LIN_description_file;
LIN_protocol_version = "2.1";
LIN_language_version = "2.1";
LIN_speed = 19.2 kbps;

Nodes {
  Master: BCM_IntLightCmd, 1 ms, 0 ms ;
  Slaves: Headliner_Lamp, Cargo_Lamp_1, Cargo_Lamp_2, Cargo_Lamp_3, Cargo_Lamp_4, IP_Light, Footwell_Left, Footwell_Right, Base_Cargo_Lamp ;
}

Signals {
  LocationId_LampLIN_HL: 8, 0, BCM_IntLightCmd, Headliner_Lamp ;
  Intensity_LampLIN_TaskLH_HL: 7, 0, BCM_IntLightCmd, Headliner_Lamp ;
  UpdateIntensity_LampLIN_HL: 1, 0, BCM_IntLightCmd, Headliner_Lamp ;
  RampDuration_LampLIN_HL: 4, 0, BCM_IntLightCmd, Headliner_Lamp ;
  Headliner_Status: 1, 0, Headliner_Lamp, BCM_IntLightCmd ;
  Headliner_Status_OverVolt: 1, 0, Headliner_Lamp, BCM_IntLightCmd ;
  Headliner_Status_OverTemp: 1, 0, Headliner_Lamp, BCM_IntLightCmd ;
  Headliner_Status_ResponseError: 1, 0, Headliner_Lamp, BCM_IntLightCmd ;
  Headliner_Intensity_TaskLH: 7, 0, Headliner_Lamp, BCM_IntLightCmd ;
  CargoLamp_1_Status: 1, 0, Cargo_Lamp_1, BCM_IntLightCmd ;
  CargoLamp_1_Status_OverVolt: 1, 0, Cargo_Lamp_1, BCM_IntLightCmd ;
  CargoLamp_1_Status_ResponseError: 1, 0, Cargo_Lamp_1, BCM_IntLightCmd ;
  CargoLamp_1_Intensity: 7, 0, Cargo_Lamp_1, BCM_IntLightCmd ;
  CargoLamp_2_Status: 1, 0, Cargo_Lamp_2, BCM_IntLightCmd ;
  CargoLamp_2_Status_OverVolt: 1, 0, Cargo_Lamp_2, BCM_IntLightCmd ;
  CargoLamp_2_Status_ResponseError: 1, 0, Cargo_Lamp_2, BCM_IntLightCmd ;
  CargoLamp_2_Intensity: 7, 0, Cargo_Lamp_2, BCM_IntLightCmd ;
  CargoLamp_3_Status: 1, 0, Cargo_Lamp_3, BCM_IntLightCmd ;
  CargoLamp_3_Status_OverVolt: 1, 0, Cargo_Lamp_3, BCM_IntLightCmd ;
  CargoLamp_3_Status_ResponseError: 1, 0, Cargo_Lamp_3, BCM_IntLightCmd ;
  CargoLamp_3_Intensity: 7, 0, Cargo_Lamp_3, BCM_IntLightCmd ;
  CargoLamp_4_Status: 1, 0, Cargo_Lamp_4, BCM_IntLightCmd ;
  CargoLamp_4_Status_OverVolt: 1, 0, Cargo_Lamp_4, BCM_IntLightCmd ;
  CargoLamp_4_Status_ResponseError: 1, 0, Cargo_Lamp_4, BCM_IntLightCmd ;
  CargoLamp_4_Intensity: 7, 0, Cargo_Lamp_4, BCM_IntLightCmd ;
  IP_Light_Status: 1, 0, IP_Light, BCM_IntLightCmd ;
  IP_Light_Status_OverVolt: 1, 0, IP_Light, BCM_IntLightCmd ;
  IP_Light_Status_ResponseError: 1, 0, IP_Light, BCM_IntLightCmd ;
  IP_Light_Intensity: 7, 0, IP_Light, BCM_IntLightCmd ;
  FWLH_Status: 1, 0, Footwell_Left, BCM_IntLightCmd ;
  FWLH_Status_OverVolt: 1, 0, Footwell_Left, BCM_IntLightCmd ;
  FWLH_Status_OverTemp: 1, 0, Footwell_Left, BCM_IntLightCmd ;
  FWLH_Status_ResponseError: 1, 0, Footwell_Left, BCM_IntLightCmd ;
  FWLH_Intensity: 7, 0, Footwell_Left, BCM_IntLightCmd ;
  FWRH_Status: 1, 0, Footwell_Right, BCM_IntLightCmd ;
  FWRH_Status_OverVolt: 1, 0, Footwell_Right, BCM_IntLightCmd ;
  FWRH_Status_OverTemp: 1, 0, Footwell_Right, BCM_IntLightCmd ;
  FWRH_Status_ResponseError: 1, 0, Footwell_Right, BCM_IntLightCmd ;
  FWRH_Intensity: 7, 0, Footwell_Right, BCM_IntLightCmd ;
  Headliner_Intensity_TaskRH: 7, 0, Headliner_Lamp, BCM_IntLightCmd ;
  Headliner_Intensity_Ambient: 7, 0, Headliner_Lamp, BCM_IntLightCmd ;
  BaseCargoLamp_Status: 1, 0, Base_Cargo_Lamp, BCM_IntLightCmd ;
  BaseCargoLamp_Status_OverVolt: 1, 0, Base_Cargo_Lamp, BCM_IntLightCmd ;
  BaseCargoLamp_Status_OverTemp: 1, 0, Base_Cargo_Lamp, BCM_IntLightCmd ;
  BaseCargoLamp_Status_ResponseError: 1, 0, Base_Cargo_Lamp, BCM_IntLightCmd ;
  BaseCargoLamp_Intensity: 7, 0, Base_Cargo_Lamp, BCM_IntLightCmd ;
  Intensity_LampLIN_TaskRH_HL: 7, 0, BCM_IntLightCmd, Headliner_Lamp ;
  Intensity_LampLIN_Ambient_HL: 7, 0, BCM_IntLightCmd, Headliner_Lamp ;
  LocationID_LampLIN: 8, 0, BCM_IntLightCmd, Cargo_Lamp_1, Cargo_Lamp_2, Cargo_Lamp_3, Cargo_Lamp_4, IP_Light, Footwell_Left, Footwell_Right, Base_Cargo_Lamp ;
  Intensity_LampLIN: 7, 0, BCM_IntLightCmd, Cargo_Lamp_1, Cargo_Lamp_2, Cargo_Lamp_3, Cargo_Lamp_4, IP_Light, Footwell_Left, Footwell_Right, Base_Cargo_Lamp ;
  UpdateIntensity_LampLIN: 1, 0, BCM_IntLightCmd, Cargo_Lamp_1, Cargo_Lamp_2, Cargo_Lamp_3, Cargo_Lamp_4, IP_Light, Footwell_Left, Footwell_Right, Base_Cargo_Lamp ;
  RampDuration_LampLIN: 4, 0, BCM_IntLightCmd, Cargo_Lamp_1, Cargo_Lamp_2, Cargo_Lamp_3, Cargo_Lamp_4, IP_Light, Footwell_Left, Footwell_Right, Base_Cargo_Lamp ;
}

Frames {
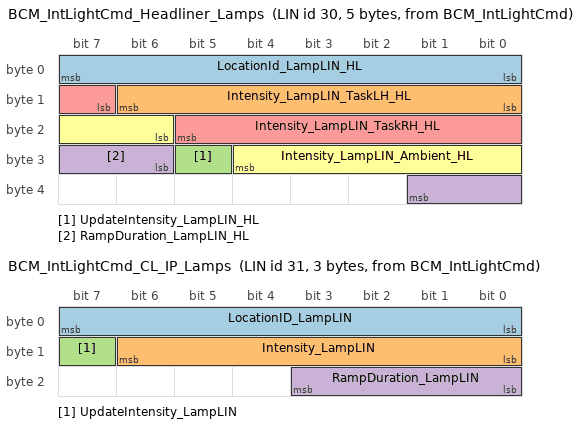
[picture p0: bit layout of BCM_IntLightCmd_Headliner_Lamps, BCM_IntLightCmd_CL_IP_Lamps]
  BCM_IntLightCmd_Headliner_Lamps: 30, BCM_IntLightCmd, 5 {
    LocationId_LampLIN_HL, 0 ;
    Intensity_LampLIN_TaskLH_HL, 8 ;
    UpdateIntensity_LampLIN_HL, 29 ;
    RampDuration_LampLIN_HL, 30 ;
    Intensity_LampLIN_TaskRH_HL, 15 ;
    Intensity_LampLIN_Ambient_HL, 22 ;
  }
  BCM_IntLightCmd_CL_IP_Lamps: 31, BCM_IntLightCmd, 3 {
    LocationID_LampLIN, 0 ;
    Intensity_LampLIN, 8 ;
    UpdateIntensity_LampLIN, 15 ;
    RampDuration_LampLIN, 16 ;
  }
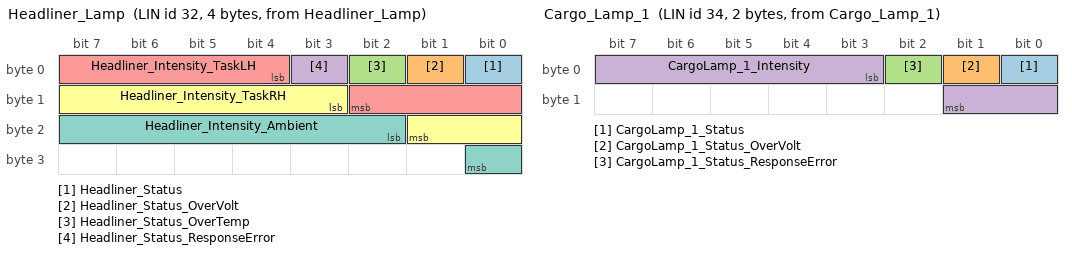
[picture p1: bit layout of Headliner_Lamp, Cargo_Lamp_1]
  Headliner_Lamp: 32, Headliner_Lamp, 4 {
    Headliner_Status, 0 ;
    Headliner_Status_OverVolt, 1 ;
    Headliner_Status_OverTemp, 2 ;
    Headliner_Status_ResponseError, 3 ;
    Headliner_Intensity_TaskLH, 4 ;
    Headliner_Intensity_TaskRH, 11 ;
    Headliner_Intensity_Ambient, 18 ;
  }
  Cargo_Lamp_1: 34, Cargo_Lamp_1, 2 {
    CargoLamp_1_Status, 0 ;
    CargoLamp_1_Status_OverVolt, 1 ;
    CargoLamp_1_Status_ResponseError, 2 ;
    CargoLamp_1_Intensity, 3 ;
  }
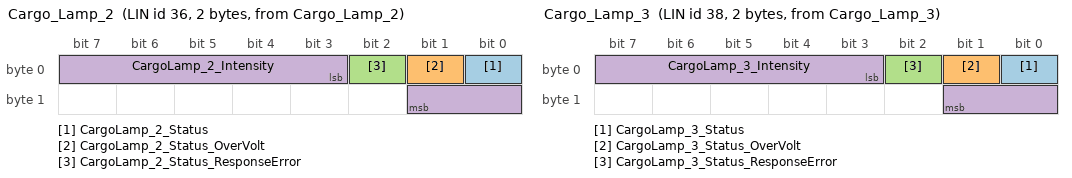
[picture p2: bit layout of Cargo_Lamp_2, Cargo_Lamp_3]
  Cargo_Lamp_2: 36, Cargo_Lamp_2, 2 {
    CargoLamp_2_Status, 0 ;
    CargoLamp_2_Status_OverVolt, 1 ;
    CargoLamp_2_Status_ResponseError, 2 ;
    CargoLamp_2_Intensity, 3 ;
  }
  Cargo_Lamp_3: 38, Cargo_Lamp_3, 2 {
    CargoLamp_3_Status, 0 ;
    CargoLamp_3_Status_OverVolt, 1 ;
    CargoLamp_3_Status_ResponseError, 2 ;
    CargoLamp_3_Intensity, 3 ;
  }
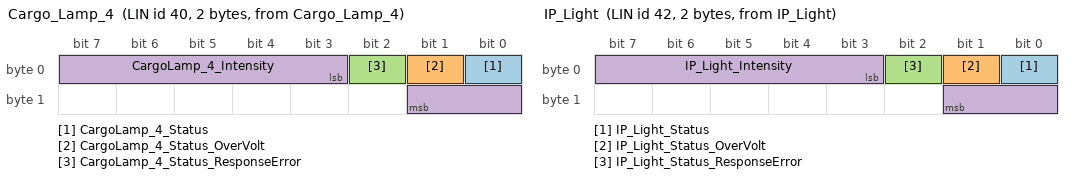
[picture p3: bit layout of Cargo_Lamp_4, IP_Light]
  Cargo_Lamp_4: 40, Cargo_Lamp_4, 2 {
    CargoLamp_4_Status, 0 ;
    CargoLamp_4_Status_OverVolt, 1 ;
    CargoLamp_4_Status_ResponseError, 2 ;
    CargoLamp_4_Intensity, 3 ;
  }
  IP_Light: 42, IP_Light, 2 {
    IP_Light_Status, 0 ;
    IP_Light_Status_OverVolt, 1 ;
    IP_Light_Status_ResponseError, 2 ;
    IP_Light_Intensity, 3 ;
  }
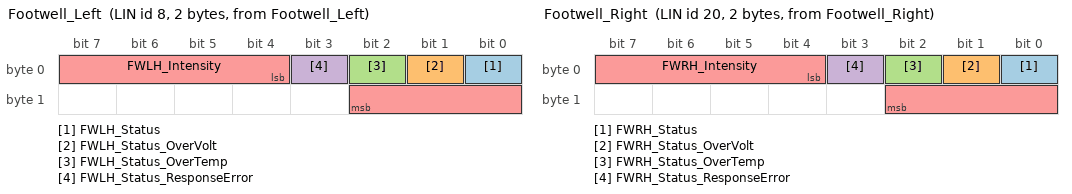
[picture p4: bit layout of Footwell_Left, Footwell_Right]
  Footwell_Left: 8, Footwell_Left, 2 {
    FWLH_Status, 0 ;
    FWLH_Status_OverVolt, 1 ;
    FWLH_Status_OverTemp, 2 ;
    FWLH_Status_ResponseError, 3 ;
    FWLH_Intensity, 4 ;
  }
  Footwell_Right: 20, Footwell_Right, 2 {
    FWRH_Status, 0 ;
    FWRH_Status_OverVolt, 1 ;
    FWRH_Status_OverTemp, 2 ;
    FWRH_Status_ResponseError, 3 ;
    FWRH_Intensity, 4 ;
  }
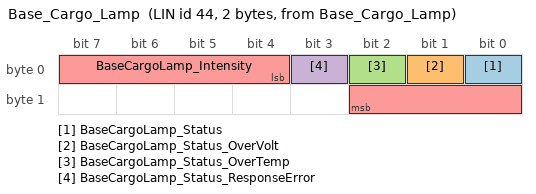
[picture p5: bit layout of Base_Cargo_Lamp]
  Base_Cargo_Lamp: 44, Base_Cargo_Lamp, 2 {
    BaseCargoLamp_Status, 0 ;
    BaseCargoLamp_Status_OverVolt, 1 ;
    BaseCargoLamp_Status_OverTemp, 2 ;
    BaseCargoLamp_Status_ResponseError, 3 ;
    BaseCargoLamp_Intensity, 4 ;
  }
}

Node_attributes {
  Headliner_Lamp{
    LIN_protocol = "2.1" ;
    configured_NAD = 0x61 ;
    initial_NAD = 0x61 ;
    product_id = 0x9C, 0x0, 0 ;
    response_error = Headliner_Status_ResponseError ;
    P2_min = 50 ms ;
    ST_min = 0 ms ;
    N_As_timeout = 1000 ms ;
    N_Cr_timeout = 1000 ms ;
    configurable_frames {
      BCM_IntLightCmd_Headliner_Lamps ;
      Headliner_Lamp ;
    }
  }
  Cargo_Lamp_1{
    LIN_protocol = "2.1" ;
    configured_NAD = 0x62 ;
    initial_NAD = 0x62 ;
    product_id = 0x9C, 0x0, 0 ;
    response_error = CargoLamp_1_Status_ResponseError ;
    P2_min = 50 ms ;
    ST_min = 0 ms ;
    N_As_timeout = 1000 ms ;
    N_Cr_timeout = 1000 ms ;
    configurable_frames {
      Cargo_Lamp_1 ;
      BCM_IntLightCmd_CL_IP_Lamps ;
    }
  }
  Cargo_Lamp_2{
    LIN_protocol = "2.1" ;
    configured_NAD = 0x63 ;
    initial_NAD = 0x63 ;
    product_id = 0x9C, 0x0, 0 ;
    response_error = CargoLamp_2_Status_ResponseError ;
    P2_min = 50 ms ;
    ST_min = 0 ms ;
    N_As_timeout = 1000 ms ;
    N_Cr_timeout = 1000 ms ;
    configurable_frames {
      Cargo_Lamp_2 ;
      BCM_IntLightCmd_CL_IP_Lamps ;
    }
  }
  Cargo_Lamp_3{
    LIN_protocol = "2.1" ;
    configured_NAD = 0x64 ;
    initial_NAD = 0x64 ;
    product_id = 0x9C, 0x0, 0 ;
    response_error = CargoLamp_3_Status_ResponseError ;
    P2_min = 50 ms ;
    ST_min = 0 ms ;
    N_As_timeout = 1000 ms ;
    N_Cr_timeout = 1000 ms ;
    configurable_frames {
      Cargo_Lamp_3 ;
      BCM_IntLightCmd_CL_IP_Lamps ;
    }
  }
  Cargo_Lamp_4{
    LIN_protocol = "2.1" ;
    configured_NAD = 0x65 ;
    initial_NAD = 0x65 ;
    product_id = 0x9C, 0x0, 0 ;
    response_error = CargoLamp_4_Status_ResponseError ;
    P2_min = 50 ms ;
    ST_min = 0 ms ;
    N_As_timeout = 1000 ms ;
    N_Cr_timeout = 1000 ms ;
    configurable_frames {
      Cargo_Lamp_4 ;
      BCM_IntLightCmd_CL_IP_Lamps ;
    }
  }
  IP_Light{
    LIN_protocol = "2.1" ;
    configured_NAD = 0x66 ;
    initial_NAD = 0x66 ;
    product_id = 0x9C, 0x0, 0 ;
    response_error = IP_Light_Status_ResponseError ;
    P2_min = 50 ms ;
    ST_min = 0 ms ;
    N_As_timeout = 1000 ms ;
    N_Cr_timeout = 1000 ms ;
    configurable_frames {
      IP_Light ;
      BCM_IntLightCmd_CL_IP_Lamps ;
    }
  }
  Footwell_Left{
    LIN_protocol = "2.1" ;
    configured_NAD = 0x67 ;
    initial_NAD = 0x67 ;
    product_id = 0x9C, 0x0, 0 ;
    response_error = FWLH_Status_ResponseError ;
    P2_min = 50 ms ;
    ST_min = 0 ms ;
    N_As_timeout = 1000 ms ;
    N_Cr_timeout = 1000 ms ;
    configurable_frames {
      Footwell_Left ;
      BCM_IntLightCmd_CL_IP_Lamps ;
    }
  }
  Footwell_Right{
    LIN_protocol = "2.1" ;
    configured_NAD = 0x68 ;
    initial_NAD = 0x68 ;
    product_id = 0x9C, 0x0, 0 ;
    response_error = FWRH_Status_ResponseError ;
    P2_min = 50 ms ;
    ST_min = 0 ms ;
    N_As_timeout = 1000 ms ;
    N_Cr_timeout = 1000 ms ;
    configurable_frames {
      Footwell_Right ;
      BCM_IntLightCmd_CL_IP_Lamps ;
    }
  }
  Base_Cargo_Lamp{
    LIN_protocol = "2.1" ;
    configured_NAD = 0x69 ;
    initial_NAD = 0x69 ;
    product_id = 0x9C, 0x0, 0 ;
    response_error = BaseCargoLamp_Status_ResponseError ;
    P2_min = 50 ms ;
    ST_min = 0 ms ;
    N_As_timeout = 1000 ms ;
    N_Cr_timeout = 1000 ms ;
    configurable_frames {
      Base_Cargo_Lamp ;
      BCM_IntLightCmd_CL_IP_Lamps ;
    }
  }
}

Schedule_tables {
 Normal_ScheduleTable {
    BCM_IntLightCmd_Headliner_Lamps delay 10 ms ;
    BCM_IntLightCmd_CL_IP_Lamps delay 10 ms ;
    Headliner_Lamp delay 10 ms ;
    BCM_IntLightCmd_CL_IP_Lamps delay 10 ms ;
    Cargo_Lamp_1 delay 10 ms ;
    BCM_IntLightCmd_CL_IP_Lamps delay 10 ms ;
    Cargo_Lamp_2 delay 10 ms ;
    BCM_IntLightCmd_CL_IP_Lamps delay 10 ms ;
    Cargo_Lamp_3 delay 10 ms ;
    BCM_IntLightCmd_CL_IP_Lamps delay 10 ms ;
    Cargo_Lamp_4 delay 10 ms ;
    BCM_IntLightCmd_CL_IP_Lamps delay 10 ms ;
    IP_Light delay 10 ms ;
    BCM_IntLightCmd_CL_IP_Lamps delay 10 ms ;
    Footwell_Left delay 10 ms ;
    BCM_IntLightCmd_CL_IP_Lamps delay 10 ms ;
    Footwell_Right delay 10 ms ;
    BCM_IntLightCmd_CL_IP_Lamps delay 10 ms ;
    Base_Cargo_Lamp delay 10 ms ;
    BCM_IntLightCmd_CL_IP_Lamps delay 10 ms ;
  }
 Diagnostic_ScheduleTable {
    SlaveResp delay 10 ms ;
    MasterReq delay 10 ms ;
  }
}

Signal_encoding_types {
  BCM_IntLightCmd_NewSignal_Encoding {
    physical_value, 0, 100, 1, 0, "%" ;
  }
  CargoLamp_Intensity_Encoding {
    physical_value, 0, 100, 1, 0, "%" ;
  }
  CargoLamp_Intensity_Encoding_1 {
    physical_value, 0, 100, 1, 0, "%" ;
  }
  CargoLamp_Status_Encoding {
    logical_value, 0, "Normal" ;
    logical_value, 1, "Fault" ;
  }
  CargoLamp_Status_Encoding_1 {
    logical_value, 0, "Normal" ;
    logical_value, 1, "Fault" ;
  }
  CargoLamp_Status_OverTemp_Encoding_1 {
    logical_value, 0, "Temp_OK" ;
    logical_value, 1, "Temp_Warning" ;
  }
  CargoLamp_Status_OverVolt_Encoding {
    logical_value, 0, "Voltage_within_Range" ;
    logical_value, 1, "Over_Voltage" ;
  }
  CargoLamp_Status_OverVolt_Encoding_1 {
    logical_value, 0, "Voltage_within_Range" ;
    logical_value, 1, "Over_Voltage" ;
  }
  CargoLamp_Status_ResponseError_Encoding {
    logical_value, 0, "No_Error" ;
    logical_value, 1, "Error" ;
  }
  CargoLamp_Status_ResponseError_Encoding_1 {
    logical_value, 0, "No_Error" ;
    logical_value, 1, "Error" ;
  }
  Headliner_Intensity_Encoding {
    physical_value, 0, 100, 1, 0, "%" ;
  }
  Headliner_Status_Encoding {
    logical_value, 0, "Normal" ;
    logical_value, 1, "Fault" ;
  }
  Headliner_Status_OverVolt_Encoding {
    logical_value, 0, "Voltage_within_Range" ;
    logical_value, 1, "Over_Voltage" ;
  }
  Headliner_Status_ResponseError_Encoding {
    logical_value, 0, "No_Error" ;
    logical_value, 1, "Error" ;
  }
  LocationId_LampLIN_Encoding {
    logical_value, 0, "Broadcast" ;
    logical_value, 1, "HeadlinerLamps" ;
    logical_value, 2, "Cargo Lamp 1" ;
    logical_value, 3, "Cargo Lamp 2" ;
    logical_value, 4, "Cargo Lamp 3" ;
    logical_value, 5, "Cargo Lamp 4" ;
    logical_value, 6, "IP Lamp" ;
    logical_value, 7, "Base Cargo" ;
    logical_value, 17, "Footwell_Left" ;
    logical_value, 18, "Footwell_Right" ;
  }
  RampDuration_LampLIN_Encoding {
    logical_value, 0, "0ms" ;
    logical_value, 1, "100ms" ;
    logical_value, 2, "250ms" ;
    logical_value, 3, "500ms" ;
    logical_value, 4, "700ms" ;
    logical_value, 5, "900ms" ;
    logical_value, 6, "1100ms" ;
    logical_value, 7, "1400ms" ;
    logical_value, 8, "1600ms" ;
    logical_value, 9, "2000ms" ;
    logical_value, 10, "2500ms" ;
    logical_value, 11, "3000ms" ;
    logical_value, 12, "3500ms" ;
    logical_value, 13, "4000ms" ;
    logical_value, 14, "5000ms" ;
    logical_value, 15, "6000ms" ;
  }
  UpdateIntensity_LampLIN_Encoding {
    logical_value, 0, "No_Action" ;
    logical_value, 1, "Update_Intensity" ;
  }
  CargoLamp_Status_OverTemp_Encoding {
    logical_value, 0, "Temp_OK" ;
    logical_value, 1, "Temp_Warning" ;
  }
}

Signal_representation {
  BCM_IntLightCmd_NewSignal_Encoding: Intensity_LampLIN_TaskLH_HL ;
  CargoLamp_Intensity_Encoding: CargoLamp_2_Intensity, CargoLamp_3_Intensity, CargoLamp_4_Intensity, IP_Light_Intensity, FWLH_Intensity, FWRH_Intensity, Intensity_LampLIN ;
  CargoLamp_Intensity_Encoding_1: CargoLamp_1_Intensity ;
  CargoLamp_Status_Encoding: CargoLamp_2_Status, CargoLamp_4_Status, IP_Light_Status, FWRH_Status ;
  CargoLamp_Status_Encoding_1: CargoLamp_1_Status ;
  CargoLamp_Status_OverTemp_Encoding_1: Headliner_Status_OverTemp, FWLH_Status_OverTemp, FWRH_Status_OverTemp, BaseCargoLamp_Status_OverTemp ;
  CargoLamp_Status_OverVolt_Encoding: CargoLamp_2_Status_OverVolt, CargoLamp_3_Status_OverVolt, CargoLamp_4_Status_OverVolt, IP_Light_Status_OverVolt, FWLH_Status_OverVolt, FWRH_Status_OverVolt ;
  CargoLamp_Status_OverVolt_Encoding_1: CargoLamp_1_Status_OverVolt ;
  CargoLamp_Status_ResponseError_Encoding: CargoLamp_2_Status_ResponseError, CargoLamp_3_Status_ResponseError, CargoLamp_4_Status_ResponseError, IP_Light_Status_ResponseError, FWLH_Status_ResponseError, FWRH_Status_ResponseError ;
  CargoLamp_Status_ResponseError_Encoding_1: CargoLamp_1_Status_ResponseError ;
  Headliner_Intensity_Encoding: Headliner_Intensity_TaskLH, Headliner_Intensity_TaskRH, Headliner_Intensity_Ambient, BaseCargoLamp_Intensity, Intensity_LampLIN_TaskRH_HL, Intensity_LampLIN_Ambient_HL ;
  Headliner_Status_Encoding: Headliner_Status, CargoLamp_3_Status, FWLH_Status, BaseCargoLamp_Status ;
  Headliner_Status_OverVolt_Encoding: Headliner_Status_OverVolt, BaseCargoLamp_Status_OverVolt ;
  Headliner_Status_ResponseError_Encoding: Headliner_Status_ResponseError, BaseCargoLamp_Status_ResponseError ;
  LocationId_LampLIN_Encoding: LocationId_LampLIN_HL, LocationID_LampLIN ;
  RampDuration_LampLIN_Encoding: RampDuration_LampLIN_HL, RampDuration_LampLIN ;
  UpdateIntensity_LampLIN_Encoding: UpdateIntensity_LampLIN_HL, UpdateIntensity_LampLIN ;
}
